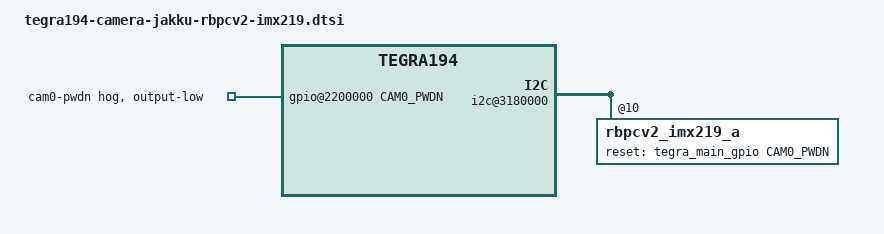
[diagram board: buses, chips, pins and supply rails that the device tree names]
/*
 * Copyright (c) 2018-2020, NVIDIA CORPORATION.  All rights reserved.
 *
 * This program is free software; you can redistribute it and/or modify
 * it under the terms of the GNU General Public License as published by
 * the Free Software Foundation; either version 2 of the License, or
 * (at your option) any later version.
 *
 * This program is distributed in the hope that it will be useful, but WITHOUT
 * ANY WARRANTY; without even the implied warranty of MERCHANTABILITY or
 * FITNESS FOR A PARTICULAR PURPOSE.  See the GNU General Public License for
 * more details.
 *
 * You should have received a copy of the GNU General Public License
 * along with this program.  If not, see <http://www.gnu.org/licenses/>.
 */

#include "tegra194-camera-rbpcv2-imx219.dtsi"

#define CAM0_PWDN	TEGRA194_MAIN_GPIO(P, 4)

/ {
	i2c@3180000 {
		rbpcv2_imx219_a@10 {
			reset-gpios = <&tegra_main_gpio CAM0_PWDN GPIO_ACTIVE_HIGH>;
		};
	};

	gpio@2200000 {
		camera-control-output-low {
			gpio-hog;
			output-low;
			gpios = <CAM0_PWDN 0>;
			label = "cam0-pwdn";
		};
	};
};
